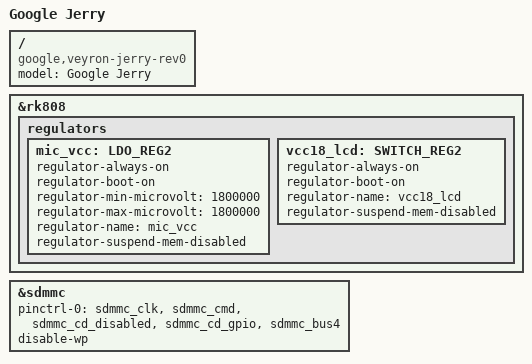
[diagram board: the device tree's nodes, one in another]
/*
 * Google Veyron Jerry Rev 0 board device tree source
 *
 * Copyright 2014 Google, Inc
 *
 * This program is free software; you can redistribute it and/or modify
 * it under the terms of the GNU General Public License version 2 as
 * published by the Free Software Foundation.
 */

/dts-v1/;
#include "rk3288-veyron-chromebook.dtsi"
#include "cros-ec-sbs.dtsi"

/ {
	model = "Google Jerry";
	compatible = "google,veyron-jerry-rev0", "google,veyron-jerry",
		     "google,veyron", "rockchip,rk3288";
};

&rk808 {
	regulators {
		mic_vcc: LDO_REG2 {
			regulator-always-on;
			regulator-boot-on;
			regulator-min-microvolt = <1800000>;
			regulator-max-microvolt = <1800000>;
			regulator-name = "mic_vcc";
			regulator-suspend-mem-disabled;
		};

		vcc18_lcd: SWITCH_REG2 {
			regulator-always-on;
			regulator-boot-on;
			regulator-name = "vcc18_lcd";
			regulator-suspend-mem-disabled;
		};

	};
};

&sdmmc {
	pinctrl-names = "default";
	pinctrl-0 = <&sdmmc_clk &sdmmc_cmd &sdmmc_cd_disabled &sdmmc_cd_gpio
			&sdmmc_bus4>;
	disable-wp;
};
